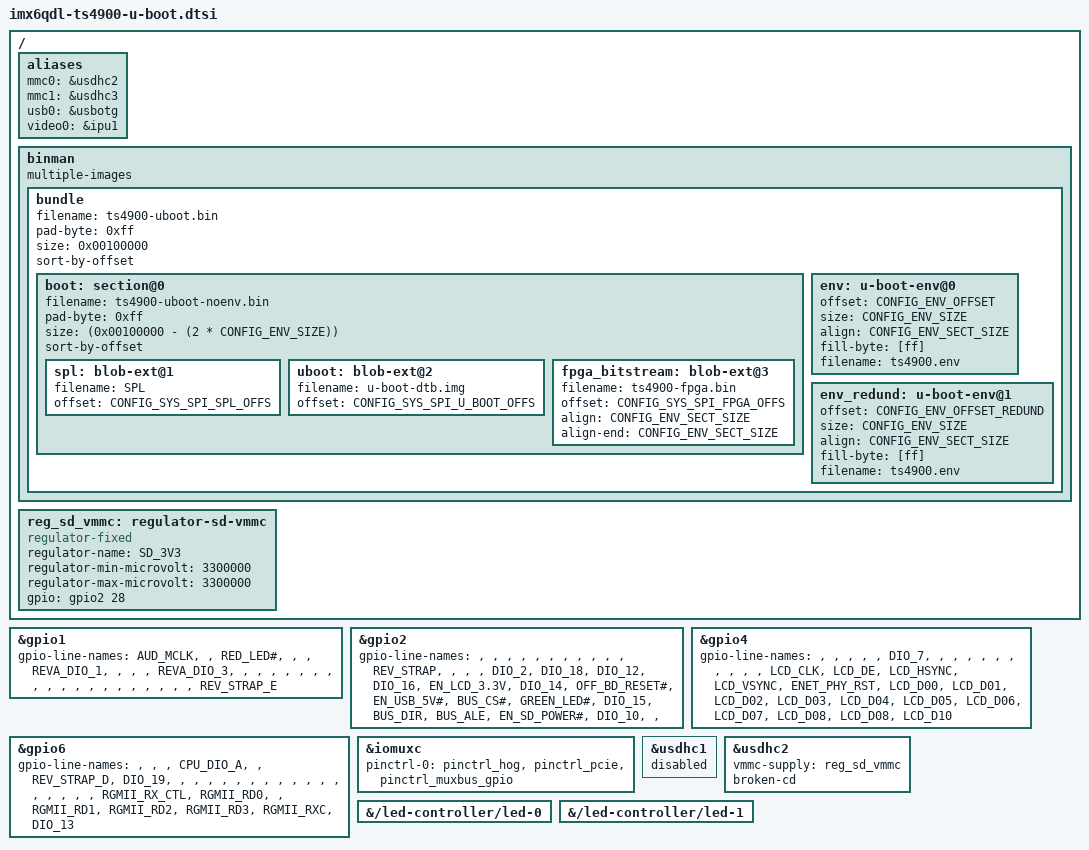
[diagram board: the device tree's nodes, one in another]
// SPDX-License-Identifier: GPL-2.0 OR X11
/*
 * Copyright (c) 2026 Technologic Systems, Inc. dba embeddedTS
 */

/ {
        aliases {
                mmc0 = &usdhc2;
                mmc1 = &usdhc3;
                usb0 = &usbotg;
                video0 = &ipu1;
        };

	binman {
		multiple-images;

		bundle {
			filename = "ts4900-uboot.bin";
			pad-byte = <0xff>;
			size = <0x00100000>;
			sort-by-offset;

			boot: section@0 {
				filename = "ts4900-uboot-noenv.bin";
				pad-byte = <0xff>;
				size = <(0x00100000 - (2 * CONFIG_ENV_SIZE))>;
				sort-by-offset;

				/* Note: the sections below must use the blob-ext
				 * node name/type. While U-Boot docs indicate that
				 * u-boot-spl and u-boot-dtb types accept a filename,
				 * the main binman script process will use the
				 * default filename if a section type has one.
				 * This happens even if we pass a filename.
				 * Becasue of this, for example, u-boot-spl will
				 * always pull in spl/u-boot-spl.bin no matter
				 * what filename we pass in the filename prop.
				 * And since the i.MX6 booting process requires
				 * the imximage format, we can't use the default
				 * files and need the processed ones.
				 */
				spl: blob-ext@1 {
					filename = "SPL";
					offset = <CONFIG_SYS_SPI_SPL_OFFS>;
				};

				uboot: blob-ext@2 {
					filename = "u-boot-dtb.img";
					offset = <CONFIG_SYS_SPI_U_BOOT_OFFS>;
				};

				fpga_bitstream: blob-ext@3 {
					filename = "ts4900-fpga.bin";
					offset = <CONFIG_SYS_SPI_FPGA_OFFS>;
					align = <CONFIG_ENV_SECT_SIZE>;
					align-end = <CONFIG_ENV_SECT_SIZE>;
				};
			};

			env: u-boot-env@0 {
				offset = <CONFIG_ENV_OFFSET>;
				size = <CONFIG_ENV_SIZE>;
				align = <CONFIG_ENV_SECT_SIZE>;
				fill-byte = [ff];
				filename = "ts4900.env";
			};

			env_redund: u-boot-env@1 {
				offset = <CONFIG_ENV_OFFSET_REDUND>;
				size = <CONFIG_ENV_SIZE>;
				align = <CONFIG_ENV_SECT_SIZE>;
				fill-byte = [ff];
				filename = "ts4900.env";
			};
		};
	};

	reg_sd_vmmc: regulator-sd-vmmc {
		compatible = "regulator-fixed";
		regulator-name = "SD_3V3";
		regulator-min-microvolt = <3300000>;
		regulator-max-microvolt = <3300000>;
		gpio = <&gpio2 28 GPIO_ACTIVE_HIGH>;
	};
};

/* We need to add line names to the GPIO banks that have our MII interface pins
 * so we can cleanly grab them as GPIO after the devicetree has loaded, but
 * before any of the networking drivers have loaded.
 */
&gpio1 {
	gpio-line-names = "AUD_MCLK", "", "RED_LED#", "", "", "REVA_DIO_1", "",
		"", "",	"REVA_DIO_3", "", "", "", "", "", "", "", "", "", "", "",
		"", "", "", "", "", "", "", "", "REV_STRAP_E";
};

&gpio2 {
	gpio-line-names = "", "", "", "", "", "", "", "", "", "", "", "REV_STRAP", "",
		"", "", "DIO_2", "DIO_18", "DIO_12", "DIO_16", "EN_LCD_3.3V",
		"DIO_14", "OFF_BD_RESET#", "EN_USB_5V#", "BUS_CS#", "GREEN_LED#",
		"DIO_15", "BUS_DIR", "BUS_ALE", "EN_SD_POWER#", "DIO_10", "", "";
};

&gpio4 {
	gpio-line-names = "", "", "", "", "", "DIO_7", "", "", "", "", "", "",
		"", "", "", "", "LCD_CLK", "LCD_DE", "LCD_HSYNC", "LCD_VSYNC",
		"ENET_PHY_RST", "LCD_D00", "LCD_D01", "LCD_D02", "LCD_D03",
		"LCD_D04", "LCD_D05", "LCD_D06", "LCD_D07", "LCD_D08", "LCD_D08",
		"LCD_D10";
};

&gpio6 {
	gpio-line-names = "", "", "", "CPU_DIO_A", "", "REV_STRAP_D", "DIO_19",
		"", "", "", "", "", "", "", "", "", "", "", "", "", "", "", "", "",
		"RGMII_RX_CTL", "RGMII_RD0", "", "RGMII_RD1", "RGMII_RD2",
		"RGMII_RD3", "RGMII_RXC", "DIO_13";
};

/* Extend our hog group to include more pins that U-Boot may need, but in the
 * Linux devicetree arn't as often used.
 */
&iomuxc {
	pinctrl-names = "default";
	pinctrl-0 = <&pinctrl_hog &pinctrl_pcie &pinctrl_muxbus_gpio>;
};

&usdhc1 {
	status = "disabled";
};

&usdhc2 {
	vmmc-supply = <&reg_sd_vmmc>;
	broken-cd;
};

/* We need to use these LED GPIO first for bbdetect. Remove the default state
 * from the DTS, and we will set it manually in board late init. */
&{/led-controller/led-0} {
	/delete-property/ default-state;
};

&{/led-controller/led-1} {
	/delete-property/ default-state;
};
